# f29h85x_gpio_data_regs register map
Vendor: Texas Instruments
Peripheral module from a debugger description file (folder C29).
Registers are 32-bit, read-write, no defined reset value unless marked. A register's access mark holds for its fields unless they carry their own. Offsets are as the file gives them; lines under a group give offsets from that group; [hi:lo] are bit positions; {n}, {i} and the like mark numbered series; 'fields as' and 'values as' point back to an identical list; <NAME> marks a mode.

## GPIO_DATA_REGS — GPIO DATA Registers
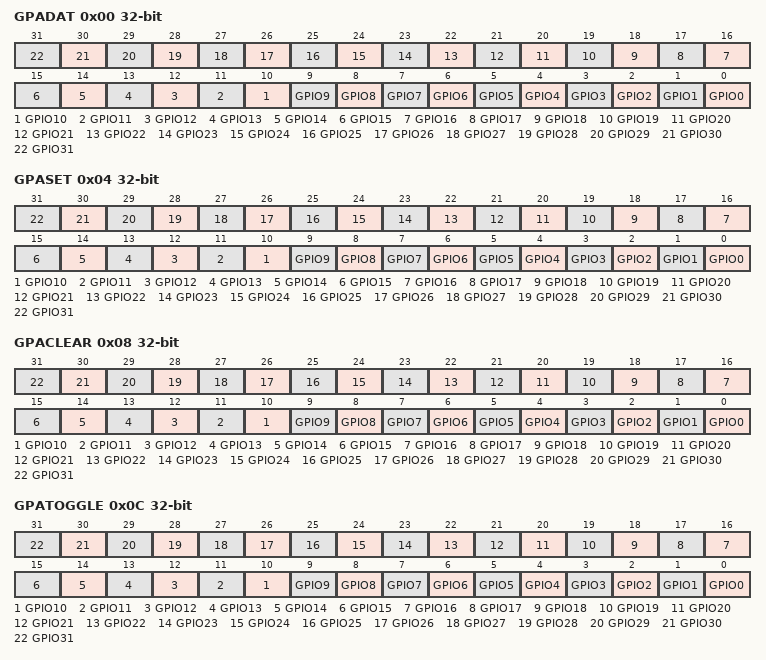
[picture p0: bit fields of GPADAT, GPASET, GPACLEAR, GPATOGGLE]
0x00 GPADAT — GPIO A Data Register (GPIO0 to 31)
  [n] GPIO{n} (n=0..31) — Data Register for this pin
0x04 GPASET — GPIO A Data Set Register (GPIO0 to 31)
  [n] GPIO{n} (n=0..31) — Output Set bit for this pin
0x08 GPACLEAR — GPIO A Data Clear Register (GPIO0 to 31)
  [n] GPIO{n} (n=0..31) — Output Clear bit for this pin
0x0C GPATOGGLE — GPIO A Data Toggle Register (GPIO0 to 31)
  [n] GPIO{n} (n=0..31) — Output Toggle bit for this pin
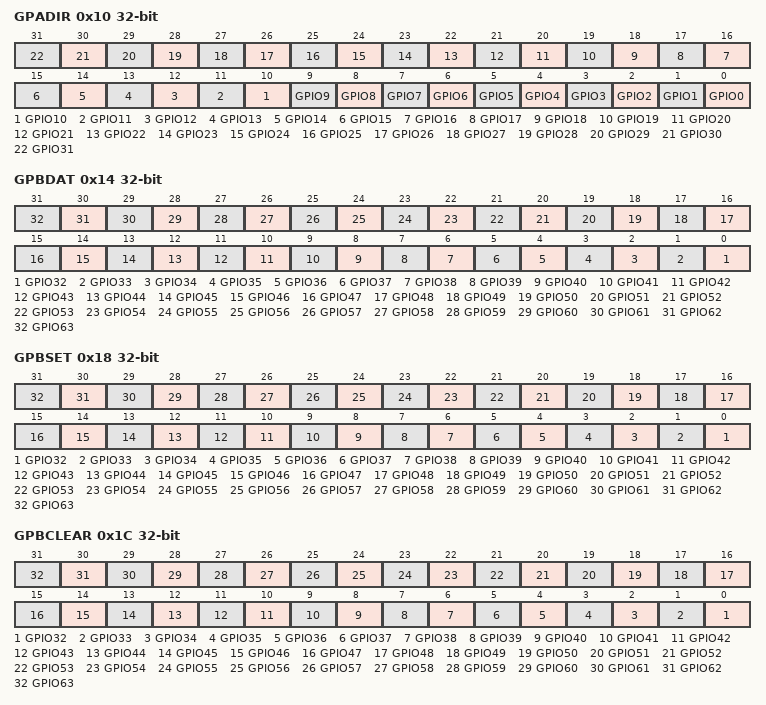
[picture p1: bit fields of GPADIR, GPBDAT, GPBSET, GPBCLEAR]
0x10 GPADIR — GPIO A Direction Register (GPIO0 to 31)
  [n] GPIO{n} (n=0..31) — Defines direction for this pin in GPIO mode
0x14 GPBDAT — GPIO B Data Register (GPIO32 to 63)
  [n-32] GPIO{n} (n=32..63) — Data Register for this pin
0x18 GPBSET — GPIO B Data Set Register (GPIO32 to 63)
  [n-32] GPIO{n} (n=32..63) — Output Set bit for this pin
0x1C GPBCLEAR — GPIO B Data Clear Register (GPIO32 to 63)
  [n-32] GPIO{n} (n=32..63) — Output Clear bit for this pin
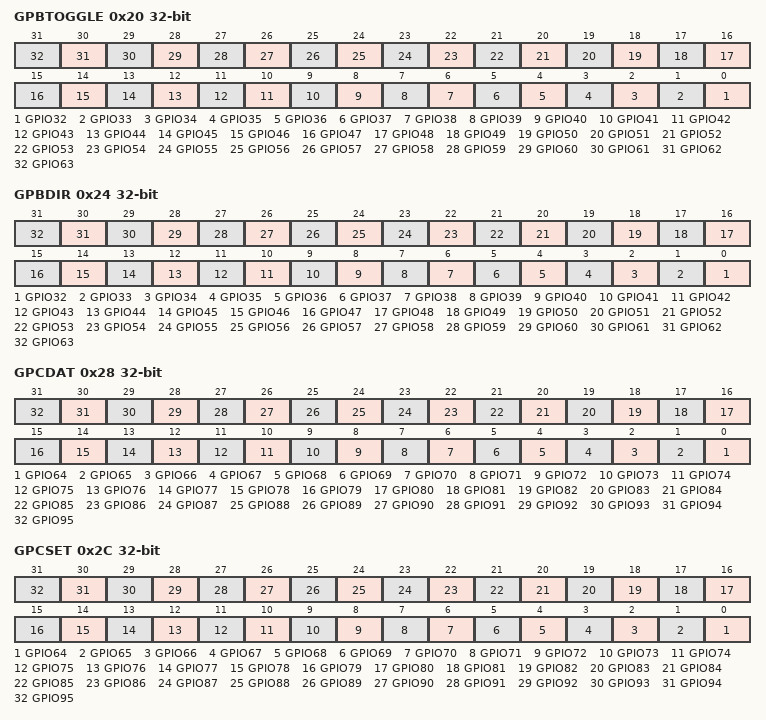
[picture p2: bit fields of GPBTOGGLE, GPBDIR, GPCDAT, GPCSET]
0x20 GPBTOGGLE — GPIO B Data Toggle Register (GPIO32 to 63)
  [n-32] GPIO{n} (n=32..63) — Output Toggle bit for this pin
0x24 GPBDIR — GPIO B Direction Register (GPIO0 to 31)
  [n-32] GPIO{n} (n=32..63) — Defines direction for this pin in GPIO mode
0x28 GPCDAT — GPIO C Data Register (GPIO64 to 95)
  [n-64] GPIO{n} (n=64..95) — Data Register for this pin
0x2C GPCSET — GPIO C Data Set Register (GPIO64 to 95)
  [n-64] GPIO{n} (n=64..95) — Output Set bit for this pin
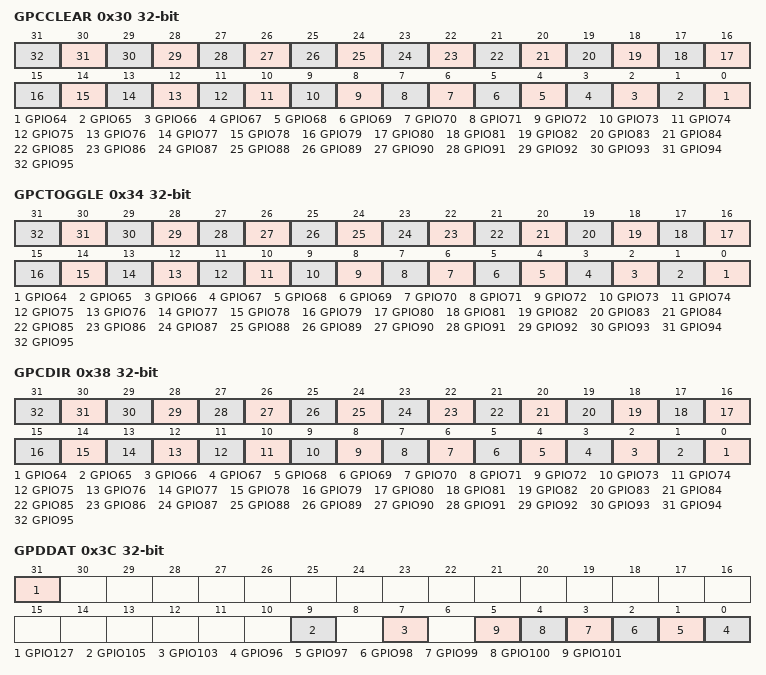
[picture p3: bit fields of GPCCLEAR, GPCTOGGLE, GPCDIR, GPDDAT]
0x30 GPCCLEAR — GPIO C Data Clear Register (GPIO64 to 95)
  [n-64] GPIO{n} (n=64..95) — Output Clear bit for this pin
0x34 GPCTOGGLE — GPIO C Data Toggle Register (GPIO64 to 95)
  [n-64] GPIO{n} (n=64..95) — Output Toggle bit for this pin
0x38 GPCDIR — GPIO C Direction Register (GPIO0 to 31)
  [n-64] GPIO{n} (n=64..95) — Defines direction for this pin in GPIO mode
0x3C GPDDAT — GPIO D Data Register (GPIO96 to 127)
  [31] GPIO127 — Data Register for this pin
  [9] GPIO105 — Data Register for this pin
  [7] GPIO103 — Data Register for this pin
  [n-96] GPIO{n} (n=96..101) — Data Register for this pin
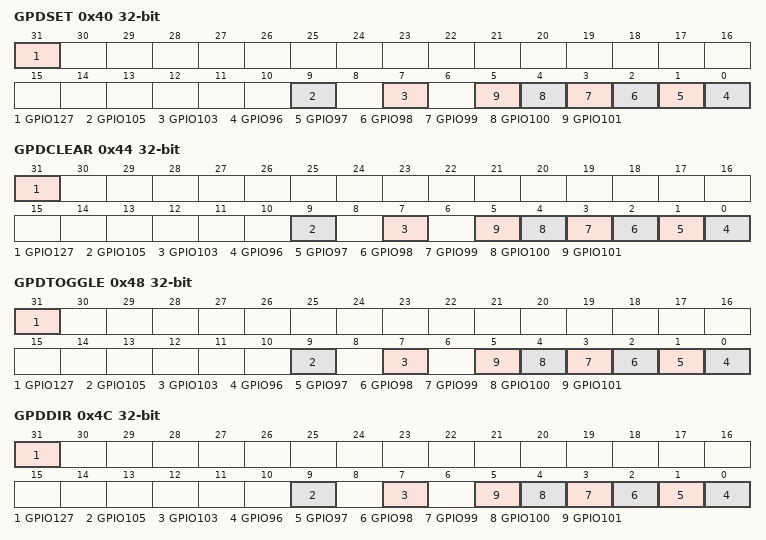
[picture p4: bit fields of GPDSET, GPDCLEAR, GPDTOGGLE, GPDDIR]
0x40 GPDSET — GPIO D Data Set Register (GPIO96 to 127)
  [31] GPIO127 — Output Set bit for this pin
  [9] GPIO105 — Output Set bit for this pin
  [7] GPIO103 — Output Set bit for this pin
  [n-96] GPIO{n} (n=96..101) — Output Set bit for this pin
0x44 GPDCLEAR — GPIO D Data Clear Register (GPIO96 to 127)
  [31] GPIO127 — Output Clear bit for this pin
  [9] GPIO105 — Output Clear bit for this pin
  [7] GPIO103 — Output Clear bit for this pin
  [n-96] GPIO{n} (n=96..101) — Output Clear bit for this pin
0x48 GPDTOGGLE — GPIO D Data Toggle Register (GPIO96 to 127)
  [31] GPIO127 — Output Toggle bit for this pin
  [9] GPIO105 — Output Toggle bit for this pin
  [7] GPIO103 — Output Toggle bit for this pin
  [n-96] GPIO{n} (n=96..101) — Output Toggle bit for this pin
0x4C GPDDIR — GPIO D Direction Register (GPIO0 to 31)
  [31] GPIO127 — Defines direction for this pin in GPIO mode
  [9] GPIO105 — Defines direction for this pin in GPIO mode
  [7] GPIO103 — Defines direction for this pin in GPIO mode
  [n-96] GPIO{n} (n=96..101) — Defines direction for this pin in GPIO mode
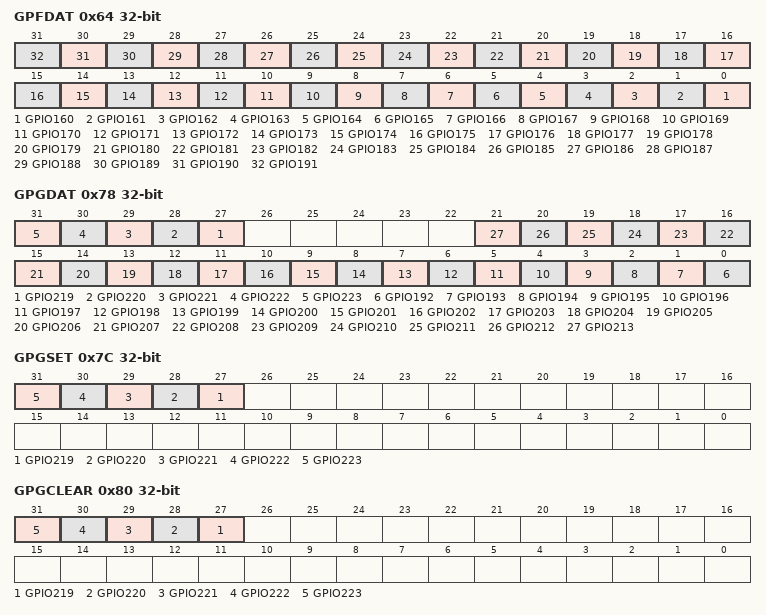
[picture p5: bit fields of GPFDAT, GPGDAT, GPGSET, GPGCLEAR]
0x64 GPFDAT — GPIO F Data Register (GPIO160 to 191)
  [n-160] GPIO{n} (n=160..191) — Data Register for this pin
0x78 GPGDAT — GPIO G Data Register (GPIO192 to 223)
  [n-192] GPIO{n} (n=219..223) — Data Register for this pin
  [n-192] GPIO{n} (n=192..213) — Data Register for this pin
0x7C GPGSET — GPIO G Data Set Register (GPIO192 to 223)
  [n-192] GPIO{n} (n=219..223) — Output Set bit for this pin
0x80 GPGCLEAR — GPIO G Data Clear Register (GPIO192 to 223)
  [n-192] GPIO{n} (n=219..223) — Output Clear bit for this pin
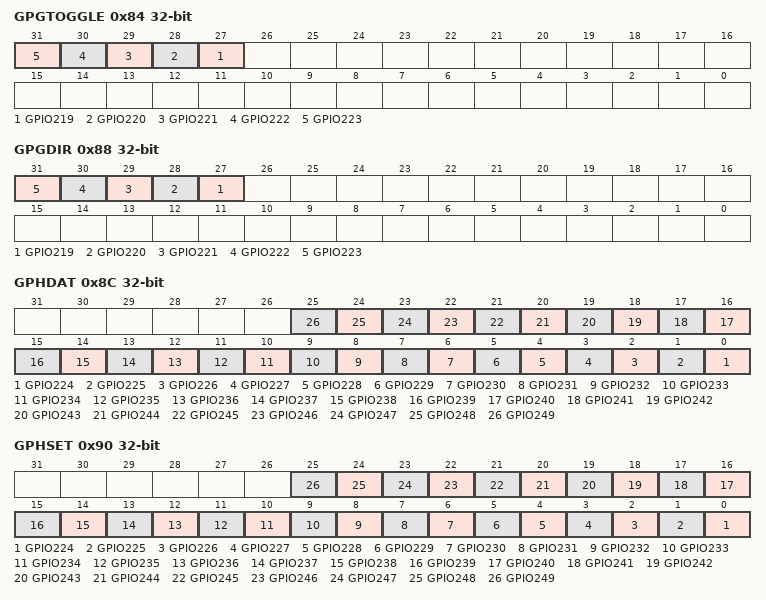
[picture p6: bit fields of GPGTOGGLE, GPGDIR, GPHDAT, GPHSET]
0x84 GPGTOGGLE — GPIO G Data Toggle Register (GPIO192 to 223)
  [n-192] GPIO{n} (n=219..223) — Output Toggle bit for this pin
0x88 GPGDIR — GPIO G Direction Register (GPIO0 to 31)
  [n-192] GPIO{n} (n=219..223) — Defines direction for this pin in GPIO mode
0x8C GPHDAT — GPIO H Data Register (GPIO224 to 255)
  [n-224] GPIO{n} (n=224..249) — Data Register for this pin
0x90 GPHSET — GPIO H Data Set Register (GPIO224 to 255)
  [n-224] GPIO{n} (n=224..249) — Output Set bit for this pin
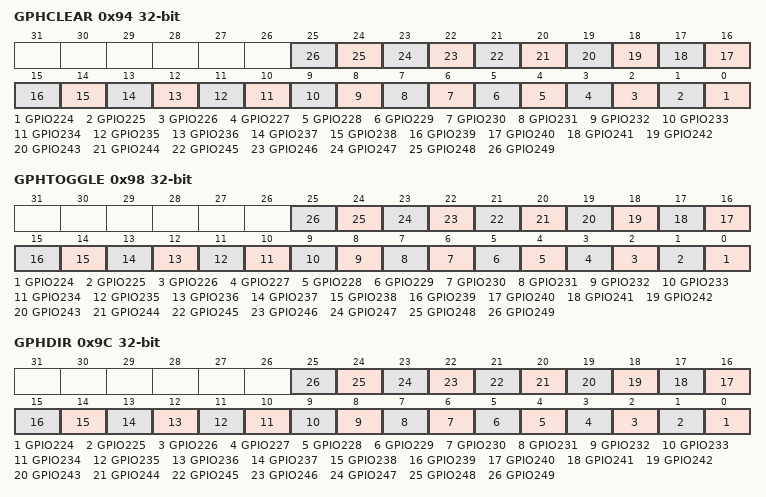
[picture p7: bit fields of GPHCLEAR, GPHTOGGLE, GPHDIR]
0x94 GPHCLEAR — GPIO H Data Clear Register (GPIO224 to 255)
  [n-224] GPIO{n} (n=224..249) — Output Clear bit for this pin
0x98 GPHTOGGLE — GPIO H Data Toggle Register (GPIO224 to 255)
  [n-224] GPIO{n} (n=224..249) — Output Toggle bit for this pin
0x9C GPHDIR — GPIO H Direction Register (GPIO0 to 31)
  [n-224] GPIO{n} (n=224..249) — Defines direction for this pin in GPIO mode
